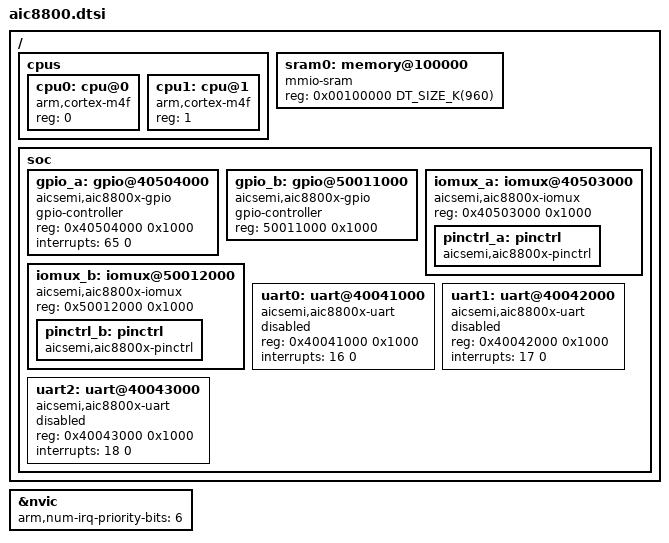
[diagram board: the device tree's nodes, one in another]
/*
 * SPDX-License-Identifier: Apache-2.0
 *
 * Copyright (c) 2022 Talpa Chen
 */

#include <arm/armv7-m.dtsi>
#include <mem.h>

/ {
	cpus {
		#address-cells = <1>;
		#size-cells = <0>;

		cpu0: cpu@0 {
			device_type = "cpu";
			compatible = "arm,cortex-m4f";
			reg = <0>;
		};

		cpu1: cpu@1 {
			device_type = "cpu";
			compatible = "arm,cortex-m4f";
			reg = <1>;
		};
	};

	sram0: memory@100000 {
		compatible = "mmio-sram";
		reg = <0x00100000 DT_SIZE_K(960)>;
	};

	soc {
		gpio_a: gpio@40504000 {
			compatible = "aicsemi,aic8800x-gpio";
			gpio-controller;
			#gpio-cells = <2>;
			reg = <0x40504000 0x1000>;
			interrupts = <65 0>;
		};
		
		gpio_b: gpio@50011000 {
			compatible = "aicsemi,aic8800x-gpio";
			gpio-controller;
			#gpio-cells = <2>;
			reg = <50011000 0x1000>;
		};
		
		iomux_a: iomux@40503000 {
			compatible = "aicsemi,aic8800x-iomux";
			#pinmux-cells = <2>;
			reg = <0x40503000 0x1000>;
			status = "okay";
			pinctrl_a: pinctrl {
				status = "okay";
				compatible = "aicsemi,aic8800x-pinctrl";
			};
		};
		
		iomux_b: iomux@50012000 {
			compatible = "aicsemi,aic8800x-iomux";
			#pinmux-cells = <2>;
			reg = <0x50012000 0x1000>;
			status = "okay";
			pinctrl_b: pinctrl {
				status = "okay";
				compatible = "aicsemi,aic8800x-pinctrl";
			};
		};

		uart0: uart@40041000 {
			compatible = "aicsemi,aic8800x-uart";
			reg = <0x40041000 0x1000>;
			interrupts = <16 0>;
			status = "disabled";
		};

		uart1: uart@40042000 {
			compatible = "aicsemi,aic8800x-uart";
			reg = <0x40042000 0x1000>;
			interrupts = <17 0>;
			status = "disabled";
		};

		uart2: uart@40043000 {
			compatible = "aicsemi,aic8800x-uart";
			reg = <0x40043000 0x1000>;
			interrupts = <18 0>;
			status = "disabled";
		};
		
		/*
		wwdg0: watchdog@40103000 {
			compatible = "aicsemi,aic8800x-watchdog";
			reg = <0x40103000 0x1000>;
			interrupts = <66 0>;
			status = "disabled";
		};
		
		wwdg1: watchdog@40104000 {
			compatible = "aicsemi,aic8800x-watchdog";
			reg = <0x40104000 0x1000>;
			interrupts = <67 0>;
			status = "disabled";
		};
		
		wwdg2: watchdog@4010A000 {
			compatible = "aicsemi,aic8800x-watchdog";
			reg = <0x4010A000 0x1000>;
			interrupts = <68 0>;
			status = "disabled";
		};
		
		wwdg3: watchdog@4010C000 {
			compatible = "aicsemi,aic8800x-watchdog";
			reg = <0x4010C000 0x1000>;
			interrupts = <30 0>;
			status = "disabled";
		};
		
		wwdg4: watchdog@40502000 {
			compatible = "aicsemi,aic8800x-watchdog";
			reg = <0x40502000 0x1000>;
			status = "disabled";
		};
		
		timer0: timer@40106000 {
			compatible = "aicsemi,aic8800x-timer";
			reg = <0x40106000 0x1000>;
			status = "disabled";
		}

		timer1: timer@40107000 {
			compatible = "aicsemi,aic8800x-timer";
			reg = <0x40107000 0x1000>;
			status = "disabled";
		}

		timer2: timer@40501000 {
			compatible = "aicsemi,aic8800x-timer";
			reg = <0x40501000 0x1000>;
			status = "disabled";
		}
		
		i2cm: i2cm@40102000 {
			compatible = "aicsemi,aic8800x-i2cm";
			reg = <0x40102000 0x1000>;
			interrupts = <71 0>;
			status = "disabled";
		};

		spi: spi@40105000 {
			compatible = "aicsemi,aic8800x-spi";
			reg = <0x40105000 0x1000>;
			interrupts = <69 0>;
			status = "disabled";
		};
		
		adc: adc@5001B000 {
			compatible = "aicsemi,aic8800x-adc";
			reg = <0x5001B000 0x1000>;
			status = "disabled";
		};
		*/
	};
};

&nvic {
	arm,num-irq-priority-bits = <6>;
};
